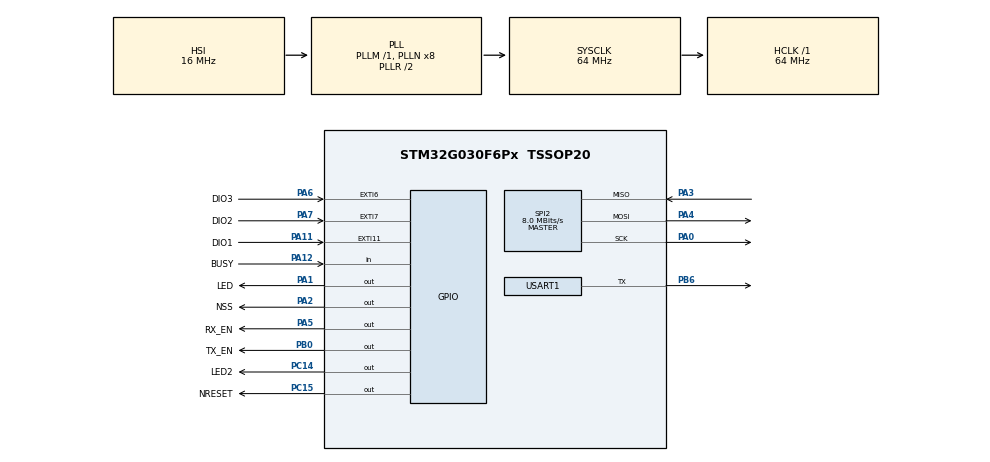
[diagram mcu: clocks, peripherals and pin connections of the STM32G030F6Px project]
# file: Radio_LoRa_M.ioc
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Mcu.Family=STM32G0
Mcu.Name=STM32G030F6Px
Mcu.Package=TSSOP20
NVIC.EXTI4_15_IRQn=true\:0\:0\:false\:false\:true\:true\:true\:true
NVIC.TIM14_IRQn=true\:0\:0\:false\:false\:true\:true\:true\:true
NVIC.TIM17_IRQn=true\:0\:0\:false\:false\:true\:true\:true\:true
NVIC.USART1_IRQn=true\:0\:0\:false\:false\:true\:true\:true\:true
PA0.GPIO_PuPd=GPIO_NOPULL
PA0.GPIO_Speed=GPIO_SPEED_FREQ_LOW
PA0.Mode=Full_Duplex_Master
PA0.PinState=GPIO_PIN_RESET
PA0.Signal=SPI2_SCK
PA1.GPIO_Label=LED
PA1.Signal=GPIO_Output
PA11\ [PA9].GPIO_Label=DIO1
PA11\ [PA9].GPIO_PuPd=GPIO_PULLDOWN
PA11\ [PA9].Signal=GPXTI11
PA12\ [PA10].GPIO_Label=BUSY
PA12\ [PA10].GPIO_PuPd=GPIO_NOPULL
PA12\ [PA10].Signal=GPIO_Input
PA13.Mode=Serial_Wire
PA13.Signal=SYS_SWDIO
PA14-BOOT0.Mode=Serial_Wire
PA14-BOOT0.Signal=SYS_SWCLK
PA14-BOOT0__PA15.StandardMode=true
PA2.GPIO_Label=NSS
PA2.GPIO_PuPd=GPIO_PULLUP
PA2.Signal=GPIO_Output
PA3.GPIO_PuPd=GPIO_NOPULL
PA3.GPIO_Speed=GPIO_SPEED_FREQ_LOW
PA3.Mode=Full_Duplex_Master
PA3.PinState=GPIO_PIN_RESET
PA3.Signal=SPI2_MISO
PA4.GPIO_PuPd=GPIO_NOPULL
PA4.GPIO_Speed=GPIO_SPEED_FREQ_LOW
PA4.Mode=Full_Duplex_Master
PA4.PinState=GPIO_PIN_RESET
PA4.Signal=SPI2_MOSI
PA5.GPIO_Label=RX_EN
PA5.Signal=GPIO_Output
PA6.GPIO_Label=DIO3
PA6.GPIO_PuPd=GPIO_PULLDOWN
PA6.Signal=GPXTI6
PA7.GPIO_Label=DIO2
PA7.GPIO_PuPd=GPIO_PULLDOWN
PA7.Signal=GPXTI7
PB0.GPIO_Label=TX_EN
PB0.Signal=GPIO_Output
PB0__PB1__PB2__PA8.StandardMode=true
PB3__PB4__PB5__PB6.StandardMode=true
PB6.GPIO_ModeDefaultOD=GPIO_MODE_AF_PP
PB6.GPIO_PuPdOD=GPIO_NOPULL
PB6.GPIO_Speed=GPIO_SPEED_FREQ_LOW
PB6.Mode=Half_duplex(single_wire_mode)
PB6.Signal=USART1_TX
PB7__PB8.StandardMode=true
PC14-OSC32_IN\ (PC14).GPIO_Label=LED2
PC14-OSC32_IN\ (PC14).Signal=GPIO_Output
PC14-OSC32_IN\ (PC14)__PB9.StandardMode=true
PC15-OSC32_OUT\ (PC15).GPIO_Label=NRESET
PC15-OSC32_OUT\ (PC15).GPIO_PuPd=GPIO_PULLUP
PC15-OSC32_OUT\ (PC15).Signal=GPIO_Output
ProjectManager.HeapSize=0x800
ProjectManager.StackSize=0xc00
ProjectManager.TargetToolchain=STM32CubeIDE
RCC.ADCFreq_Value=64000000
RCC.AHBFreq_Value=64000000
RCC.CortexFreq_Value=64000000
RCC.EXTERNAL_CLOCK_VALUE=12288000
RCC.HCLKFreq_Value=64000000
RCC.HSE_VALUE=8000000
RCC.HSI_VALUE=16000000
RCC.LSE_VALUE=32768
RCC.SYSCLKFreq_VALUE=64000000
RCC.SYSCLKSource=RCC_SYSCLKSOURCE_PLLCLK
RCC.VCOOutputFreq_Value=128000000
SPI2.BaudRatePrescaler=SPI_BAUDRATEPRESCALER_8
SPI2.CLKPolarity=SPI_POLARITY_LOW
SPI2.CRCCalculation=SPI_CRCCALCULATION_DISABLE
SPI2.CalculateBaudRate=8.0 MBits/s
SPI2.Direction=SPI_DIRECTION_2LINES
SPI2.Mode=SPI_MODE_MASTER
SPI2.VirtualType=VM_MASTER
TIM14.Channel=TIM_CHANNEL_1
TIM14.Prescaler=64-1
TIM16.Period=6666
TIM16.Prescaler=0
TIM17.Channel=TIM_CHANNEL_1
TIM17.Prescaler=64000
TIM17.Pulse=1000
USART1.BaudRate=100000
USART1.DMADisableonRxErrorParam=ADVFEATURE_DMA_DISABLEONRXERROR
USART1.Mode=MODE_TX
USART1.Parity=PARITY_EVEN
USART1.StopBits=STOPBITS_2
USART1.TxPinLevelInvertParam=ADVFEATURE_TXINV_ENABLE
USART1.VirtualMode-Half_duplex(single_wire_mode)=VM_ASYNC
USART1.WordLength=WORDLENGTH_9B
VP_TIM14_VS_ClockSourceINT.Mode=Enable_Timer
VP_TIM14_VS_no_output1.Mode=Output Compare1 No Output
VP_TIM16_VS_ClockSourceINT.Mode=Enable_Timer
VP_TIM17_VS_ClockSourceINT.Mode=Enable_Timer
VP_TIM17_VS_no_output1.Mode=Output Compare1 No Output
board=custom

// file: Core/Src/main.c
/* USER CODE BEGIN Header */
/**
  ******************************************************************************
  * @file           : main.c
  * @brief          : Main program body
  ******************************************************************************
  * @attention
  *
  * Copyright (c) 2023 STMicroelectronics.
  * All rights reserved.
  *
  * This software is licensed under terms that can be found in the LICENSE file
  * in the root directory of this software component.
  * If no LICENSE file comes with this software, it is provided AS-IS.
  *
  ******************************************************************************
  */
/* USER CODE END Header */
#include "main.h"

SPI_HandleTypeDef hspi2;

TIM_HandleTypeDef htim14;
TIM_HandleTypeDef htim16;
TIM_HandleTypeDef htim17;

UART_HandleTypeDef huart1;

void SystemClock_Config(void);
static void MX_GPIO_Init(void);
static void MX_SPI2_Init(void);
static void MX_USART1_UART_Init(void);
static void MX_TIM14_Init(void);
static void MX_TIM17_Init(void);
static void MX_TIM16_Init(void);

/* USER CODE BEGIN 0 */
//void SysTick_Handler(void) {
//    HAL_IncTick();
//}
/* USER CODE END 0 */

int main(void)
{

  /* MCU Configuration--------------------------------------------------------*/

  /* Reset of all peripherals, Initializes the Flash interface and the Systick. */
  HAL_Init();

  /* Configure the system clock */
  SystemClock_Config();

  /* Initialize all configured peripherals */
  MX_GPIO_Init();
  MX_SPI2_Init();
  MX_USART1_UART_Init();
  MX_TIM14_Init();
  MX_TIM17_Init();
  MX_TIM16_Init();

  /* Infinite loop */
  /* USER CODE BEGIN WHILE */

 // for( int i = 0; i < 65000; i++)
	//  __asm("NOP");

  //HAL_Delay(2);
  maincpp();
  while (1)
  {
    /* USER CODE END WHILE */

  }
}

void SystemClock_Config(void)
{
  RCC_OscInitTypeDef RCC_OscInitStruct = {0};
  RCC_ClkInitTypeDef RCC_ClkInitStruct = {0};

  /** Configure the main internal regulator output voltage
  */
  HAL_PWREx_ControlVoltageScaling(PWR_REGULATOR_VOLTAGE_SCALE1);

  /** Initializes the RCC Oscillators according to the specified parameters
  * in the RCC_OscInitTypeDef structure.
  */
  RCC_OscInitStruct.OscillatorType = RCC_OSCILLATORTYPE_HSI;
  RCC_OscInitStruct.HSIState = RCC_HSI_ON;
  RCC_OscInitStruct.HSIDiv = RCC_HSI_DIV1;
  RCC_OscInitStruct.HSICalibrationValue = RCC_HSICALIBRATION_DEFAULT;
  RCC_OscInitStruct.PLL.PLLState = RCC_PLL_ON;
  RCC_OscInitStruct.PLL.PLLSource = RCC_PLLSOURCE_HSI;
  RCC_OscInitStruct.PLL.PLLM = RCC_PLLM_DIV1;
  RCC_OscInitStruct.PLL.PLLN = 8;
  RCC_OscInitStruct.PLL.PLLP = RCC_PLLP_DIV2;
  RCC_OscInitStruct.PLL.PLLR = RCC_PLLR_DIV2;
  if (HAL_RCC_OscConfig(&RCC_OscInitStruct) != HAL_OK)
  {
    Error_Handler();
  }

  /** Initializes the CPU, AHB and APB buses clocks
  */
  RCC_ClkInitStruct.ClockType = RCC_CLOCKTYPE_HCLK|RCC_CLOCKTYPE_SYSCLK
                              |RCC_CLOCKTYPE_PCLK1;
  RCC_ClkInitStruct.SYSCLKSource = RCC_SYSCLKSOURCE_PLLCLK;
  RCC_ClkInitStruct.AHBCLKDivider = RCC_SYSCLK_DIV1;
  RCC_ClkInitStruct.APB1CLKDivider = RCC_HCLK_DIV1;

  if (HAL_RCC_ClockConfig(&RCC_ClkInitStruct, FLASH_LATENCY_2) != HAL_OK)
  {
    Error_Handler();
  }
}

static void MX_SPI2_Init(void)
{

  /* SPI2 parameter configuration*/
  hspi2.Instance = SPI2;
  hspi2.Init.Mode = SPI_MODE_MASTER;
  hspi2.Init.Direction = SPI_DIRECTION_2LINES;
  hspi2.Init.DataSize = SPI_DATASIZE_8BIT;
  hspi2.Init.CLKPolarity = SPI_POLARITY_LOW;
  hspi2.Init.CLKPhase = SPI_PHASE_1EDGE;
  hspi2.Init.NSS = SPI_NSS_SOFT;
  hspi2.Init.BaudRatePrescaler = SPI_BAUDRATEPRESCALER_8;
  hspi2.Init.FirstBit = SPI_FIRSTBIT_MSB;
  hspi2.Init.TIMode = SPI_TIMODE_DISABLE;
  hspi2.Init.CRCCalculation = SPI_CRCCALCULATION_DISABLE;
  hspi2.Init.CRCPolynomial = 7;
  hspi2.Init.CRCLength = SPI_CRC_LENGTH_DATASIZE;
  hspi2.Init.NSSPMode = SPI_NSS_PULSE_ENABLE;
  if (HAL_SPI_Init(&hspi2) != HAL_OK)
  {
    Error_Handler();
  }

}

static void MX_TIM14_Init(void)
{

  TIM_OC_InitTypeDef sConfigOC = {0};

  htim14.Instance = TIM14;
  htim14.Init.Prescaler = 64-1;
  htim14.Init.CounterMode = TIM_COUNTERMODE_UP;
  htim14.Init.Period = 65535;
  htim14.Init.ClockDivision = TIM_CLOCKDIVISION_DIV1;
  htim14.Init.AutoReloadPreload = TIM_AUTORELOAD_PRELOAD_DISABLE;
  if (HAL_TIM_Base_Init(&htim14) != HAL_OK)
  {
    Error_Handler();
  }
  if (HAL_TIM_OC_Init(&htim14) != HAL_OK)
  {
    Error_Handler();
  }
  sConfigOC.OCMode = TIM_OCMODE_TIMING;
  sConfigOC.Pulse = 0;
  sConfigOC.OCPolarity = TIM_OCPOLARITY_HIGH;
  sConfigOC.OCFastMode = TIM_OCFAST_DISABLE;
  if (HAL_TIM_OC_ConfigChannel(&htim14, &sConfigOC, TIM_CHANNEL_1) != HAL_OK)
  {
    Error_Handler();
  }

}

static void MX_TIM16_Init(void)
{

  htim16.Instance = TIM16;
  htim16.Init.Prescaler = 0;
  htim16.Init.CounterMode = TIM_COUNTERMODE_UP;
  htim16.Init.Period = 6666;
  htim16.Init.ClockDivision = TIM_CLOCKDIVISION_DIV1;
  htim16.Init.RepetitionCounter = 0;
  htim16.Init.AutoReloadPreload = TIM_AUTORELOAD_PRELOAD_DISABLE;
  if (HAL_TIM_Base_Init(&htim16) != HAL_OK)
  {
    Error_Handler();
  }

}

static void MX_TIM17_Init(void)
{

  TIM_OC_InitTypeDef sConfigOC = {0};
  TIM_BreakDeadTimeConfigTypeDef sBreakDeadTimeConfig = {0};

  htim17.Instance = TIM17;
  htim17.Init.Prescaler = 64000;
  htim17.Init.CounterMode = TIM_COUNTERMODE_UP;
  htim17.Init.Period = 65535;
  htim17.Init.ClockDivision = TIM_CLOCKDIVISION_DIV1;
  htim17.Init.RepetitionCounter = 0;
  htim17.Init.AutoReloadPreload = TIM_AUTORELOAD_PRELOAD_DISABLE;
  if (HAL_TIM_Base_Init(&htim17) != HAL_OK)
  {
    Error_Handler();
  }
  if (HAL_TIM_OC_Init(&htim17) != HAL_OK)
  {
    Error_Handler();
  }
  sConfigOC.OCMode = TIM_OCMODE_TIMING;
  sConfigOC.Pulse = 1000;
  sConfigOC.OCPolarity = TIM_OCPOLARITY_HIGH;
  sConfigOC.OCNPolarity = TIM_OCNPOLARITY_HIGH;
  sConfigOC.OCFastMode = TIM_OCFAST_DISABLE;
  sConfigOC.OCIdleState = TIM_OCIDLESTATE_RESET;
  sConfigOC.OCNIdleState = TIM_OCNIDLESTATE_RESET;
  if (HAL_TIM_OC_ConfigChannel(&htim17, &sConfigOC, TIM_CHANNEL_1) != HAL_OK)
  {
    Error_Handler();
  }
  sBreakDeadTimeConfig.OffStateRunMode = TIM_OSSR_DISABLE;
  sBreakDeadTimeConfig.OffStateIDLEMode = TIM_OSSI_DISABLE;
  sBreakDeadTimeConfig.LockLevel = TIM_LOCKLEVEL_OFF;
  sBreakDeadTimeConfig.DeadTime = 0;
  sBreakDeadTimeConfig.BreakState = TIM_BREAK_DISABLE;
  sBreakDeadTimeConfig.BreakPolarity = TIM_BREAKPOLARITY_HIGH;
  sBreakDeadTimeConfig.BreakFilter = 0;
  sBreakDeadTimeConfig.AutomaticOutput = TIM_AUTOMATICOUTPUT_DISABLE;
  if (HAL_TIMEx_ConfigBreakDeadTime(&htim17, &sBreakDeadTimeConfig) != HAL_OK)
  {
    Error_Handler();
  }

}

static void MX_USART1_UART_Init(void)
{

  huart1.Instance = USART1;
  huart1.Init.BaudRate = 100000;
  huart1.Init.WordLength = UART_WORDLENGTH_9B;
  huart1.Init.StopBits = UART_STOPBITS_2;
  huart1.Init.Parity = UART_PARITY_EVEN;
  huart1.Init.Mode = UART_MODE_TX;
  huart1.Init.HwFlowCtl = UART_HWCONTROL_NONE;
  huart1.Init.OverSampling = UART_OVERSAMPLING_16;
  huart1.Init.OneBitSampling = UART_ONE_BIT_SAMPLE_DISABLE;
  huart1.Init.ClockPrescaler = UART_PRESCALER_DIV1;
  huart1.AdvancedInit.AdvFeatureInit = UART_ADVFEATURE_TXINVERT_INIT|UART_ADVFEATURE_DMADISABLEONERROR_INIT;
  huart1.AdvancedInit.TxPinLevelInvert = UART_ADVFEATURE_TXINV_ENABLE;
  huart1.AdvancedInit.DMADisableonRxError = UART_ADVFEATURE_DMA_DISABLEONRXERROR;
  if (HAL_HalfDuplex_Init(&huart1) != HAL_OK)
  {
    Error_Handler();
  }
  if (HAL_UARTEx_SetTxFifoThreshold(&huart1, UART_TXFIFO_THRESHOLD_1_8) != HAL_OK)
  {
    Error_Handler();
  }
  if (HAL_UARTEx_SetRxFifoThreshold(&huart1, UART_RXFIFO_THRESHOLD_1_8) != HAL_OK)
  {
    Error_Handler();
  }
  if (HAL_UARTEx_DisableFifoMode(&huart1) != HAL_OK)
  {
    Error_Handler();
  }

}

static void MX_GPIO_Init(void)
{
  GPIO_InitTypeDef GPIO_InitStruct = {0};

  /* GPIO Ports Clock Enable */
  __HAL_RCC_GPIOC_CLK_ENABLE();
  __HAL_RCC_GPIOA_CLK_ENABLE();
  __HAL_RCC_GPIOB_CLK_ENABLE();

  /*Configure GPIO pin Output Level */
  HAL_GPIO_WritePin(GPIOC, LED2_Pin|NRESET_Pin, GPIO_PIN_RESET);

  /*Configure GPIO pin Output Level */
  HAL_GPIO_WritePin(GPIOA, LED_Pin|NSS_Pin|RX_EN_Pin, GPIO_PIN_RESET);

  /*Configure GPIO pin Output Level */
  HAL_GPIO_WritePin(TX_EN_GPIO_Port, TX_EN_Pin, GPIO_PIN_RESET);

  /*Configure GPIO pin : LED2_Pin */
  GPIO_InitStruct.Pin = LED2_Pin;
  GPIO_InitStruct.Mode = GPIO_MODE_OUTPUT_PP;
  GPIO_InitStruct.Pull = GPIO_NOPULL;
  GPIO_InitStruct.Speed = GPIO_SPEED_FREQ_LOW;
  HAL_GPIO_Init(LED2_GPIO_Port, &GPIO_InitStruct);

  /*Configure GPIO pin : NRESET_Pin */
  GPIO_InitStruct.Pin = NRESET_Pin;
  GPIO_InitStruct.Mode = GPIO_MODE_OUTPUT_PP;
  GPIO_InitStruct.Pull = GPIO_PULLUP;
  GPIO_InitStruct.Speed = GPIO_SPEED_FREQ_LOW;
  HAL_GPIO_Init(NRESET_GPIO_Port, &GPIO_InitStruct);

  /*Configure GPIO pins : LED_Pin RX_EN_Pin */
  GPIO_InitStruct.Pin = LED_Pin|RX_EN_Pin;
  GPIO_InitStruct.Mode = GPIO_MODE_OUTPUT_PP;
  GPIO_InitStruct.Pull = GPIO_NOPULL;
  GPIO_InitStruct.Speed = GPIO_SPEED_FREQ_LOW;
  HAL_GPIO_Init(GPIOA, &GPIO_InitStruct);

  /*Configure GPIO pin : NSS_Pin */
  GPIO_InitStruct.Pin = NSS_Pin;
  GPIO_InitStruct.Mode = GPIO_MODE_OUTPUT_PP;
  GPIO_InitStruct.Pull = GPIO_PULLUP;
  GPIO_InitStruct.Speed = GPIO_SPEED_FREQ_LOW;
  HAL_GPIO_Init(NSS_GPIO_Port, &GPIO_InitStruct);

  /*Configure GPIO pins : DIO3_Pin DIO2_Pin DIO1_Pin */
  GPIO_InitStruct.Pin = DIO3_Pin|DIO2_Pin|DIO1_Pin;
  GPIO_InitStruct.Mode = GPIO_MODE_IT_RISING;
  GPIO_InitStruct.Pull = GPIO_PULLDOWN;
  HAL_GPIO_Init(GPIOA, &GPIO_InitStruct);

  /*Configure GPIO pin : TX_EN_Pin */
  GPIO_InitStruct.Pin = TX_EN_Pin;
  GPIO_InitStruct.Mode = GPIO_MODE_OUTPUT_PP;
  GPIO_InitStruct.Pull = GPIO_NOPULL;
  GPIO_InitStruct.Speed = GPIO_SPEED_FREQ_LOW;
  HAL_GPIO_Init(TX_EN_GPIO_Port, &GPIO_InitStruct);

  /*Configure GPIO pin : BUSY_Pin */
  GPIO_InitStruct.Pin = BUSY_Pin;
  GPIO_InitStruct.Mode = GPIO_MODE_INPUT;
  GPIO_InitStruct.Pull = GPIO_NOPULL;
  HAL_GPIO_Init(BUSY_GPIO_Port, &GPIO_InitStruct);

  /* EXTI interrupt init*/
  HAL_NVIC_SetPriority(EXTI4_15_IRQn, 0, 0);
  HAL_NVIC_EnableIRQ(EXTI4_15_IRQn);

}

void Error_Handler(void)
{
  __disable_irq();
  while (1)
  {
  }
}
